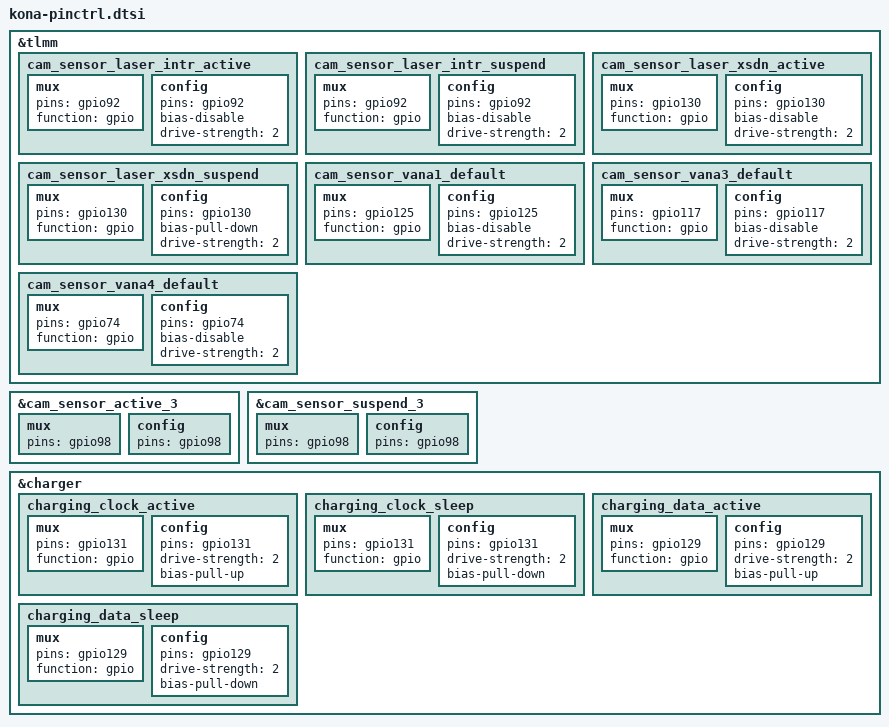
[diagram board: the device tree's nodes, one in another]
&tlmm {
	cam_sensor_laser_intr_active: cam_sensor_laser_intr_active {
		mux {
			pins = "gpio92";
			function = "gpio";
		};

		config {
			pins = "gpio92";
			bias-disable; /* No PULL */
			drive-strength = <2>; /* 2 MA */
		};
	};

	cam_sensor_laser_intr_suspend: cam_sensor_laser_intr_suspend{
		mux {
			pins = "gpio92";
			function = "gpio";
		};

		config {
			pins = "gpio92";
			bias-disable; /* PULL DOWN */
			drive-strength = <2>; /* 2 MA */
		};
	};

	cam_sensor_laser_xsdn_active: cam_sensor_laser_xsdn_active {
		mux {
			pins = "gpio130";
			function = "gpio";
		};

		config {
			pins = "gpio130";
			bias-disable; /* No PULL */
			drive-strength = <2>; /* 2 MA */
		};
	};

	cam_sensor_laser_xsdn_suspend: cam_sensor_laser_xsdn_suspend{
		mux {
			pins = "gpio130";
			function = "gpio";
		};

		config {
			pins = "gpio130";
			bias-pull-down; /* PULL DOWN */
			drive-strength = <2>; /* 2 MA */
		};
	};

	cam_sensor_vana1_default: cam_sensor_vana1_default {
		/*  VIO LDO */
		mux {
			pins = "gpio125";
			function = "gpio";
		};

		config {
			pins = "gpio125";
			bias-disable; /* No PULL */
			drive-strength = <2>; /* 2 MA */
		};
	};

	cam_sensor_vana3_default: cam_sensor_vana3_default {
		/*  VIO LDO */
		mux {
			pins = "gpio117";
			function = "gpio";
		};

		config {
			pins = "gpio117";
			bias-disable; /* No PULL */
			drive-strength = <2>; /* 2 MA */
		};
	};

	cam_sensor_vana4_default: cam_sensor_vana4_default {
		/*  VIO LDO */
		mux {
			pins = "gpio74";
			function = "gpio";
		};

		config {
			pins = "gpio74";
			bias-disable; /* No PULL */
			drive-strength = <2>; /* 2 MA */
		};
	};
};

&cam_sensor_active_3 {
	mux {
		pins = "gpio98";
	};

	config {
		pins = "gpio98";
	};
};

&cam_sensor_suspend_3 {
	mux {
		pins = "gpio98";
	};

	config {
		pins = "gpio98";
	};
};

&charger {
	charging_clock_active: charging_clock_active {
		mux {
			pins = "gpio131";
			function = "gpio";
		};

		config {
			pins = "gpio131";
			drive-strength = <2>;
			bias-pull-up;
		};
	};

	charging_clock_sleep: charging_clock_sleep {
		mux {
			pins = "gpio131";
			function = "gpio";
		};

		config {
			pins = "gpio131";
			drive-strength = <2>;
			bias-pull-down;
		};
	};

	charging_data_active: charging_data_active {
		mux {
			pins = "gpio129";
			function = "gpio";
		};

		config {
			pins = "gpio129";
			drive-strength = <2>;
			bias-pull-up;
		};
	};

	charging_data_sleep: charging_data_sleep {
		mux {
			pins = "gpio129";
			function = "gpio";
		};

		config {
			pins = "gpio129";
			drive-strength = <2>;
			bias-pull-down;
		};
	};
};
